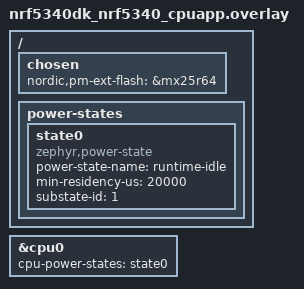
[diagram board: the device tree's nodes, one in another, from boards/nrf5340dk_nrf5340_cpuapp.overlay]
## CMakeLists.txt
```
# SPDX-License-Identifier: Apache-2.0

cmake_minimum_required(VERSION 3.20.0)
set(CMAKE_OBJCOPY arm-zephyr-eabi-objcopy)

set_property(GLOBAL 
    APPEND 
    PROPERTY extra_post_build_commands    
    COMMAND ${CMAKE_OBJCOPY} --output-target=binary --remove-section=_EXTFLASH_TEXT_SECTION_NAME --remove-section=_EXTFLASH_RODATA_SECTION_NAME --remove-section=.comment --remove-section=COMMON --remove-section=.eh_frame zephyr.elf zephyr.bin
    COMMAND ${CMAKE_OBJCOPY} --output-target=ihex --remove-section=_EXTFLASH_TEXT_SECTION_NAME --remove-section=_EXTFLASH_RODATA_SECTION_NAME --remove-section=.comment --remove-section=COMMON --remove-section=.eh_frame zephyr.elf zephyr.hex    
    COMMAND ${CMAKE_OBJCOPY} --output-target=binary --only-section=_EXTFLASH_TEXT_SECTION_NAME --only-section=_EXTFLASH_RODATA_SECTION_NAME zephyr.elf xip.bin
    COMMAND ${CMAKE_OBJCOPY} --output-target=ihex --only-section=_EXTFLASH_TEXT_SECTION_NAME --only-section=_EXTFLASH_RODATA_SECTION_NAME zephyr.elf xip.hex
    COMMAND python $ENV{ZEPHYR_BASE}/../bootloader/mcuboot/scripts/imgtool.py sign --key $ENV{ZEPHYR_BASE}/../bootloader/mcuboot/root-ec-p256.pem --header-size 0x200 --align 4 --version 0.0.0+0 --pad-header --slot-size 0x100000 xip.bin xip_signed.bin
    COMMAND ${CMAKE_OBJCOPY} --input-target=binary --output-target=ihex --change-address 0x10000000 --gap-fill=0xff xip_signed.bin xip_signed.hex
    COMMAND ${CMAKE_OBJCOPY} --input-target=binary --output-target=ihex --change-address 0x10230000 --gap-fill=0xff xip_signed.bin xip_moved_test_update.hex
    COMMAND echo "####### XIP hex generation #######"
)

SET(hci_rpmsg_b0n_OVERLAY_CONFIG "${CMAKE_CURRENT_SOURCE_DIR}/child_image/b0n.conf")

find_package(Zephyr REQUIRED HINTS $ENV{ZEPHYR_BASE})
project(xip_dma)

FILE(GLOB app_sources src/*.c)
target_sources(app PRIVATE ${app_sources})

# Run adc_thread from the external flash (XIP). No need to copy.
# zephyr_code_relocate(src/adc_thread.c EXTFLASH_TEXT NOCOPY)

# But still relocate (copy) the data to RAM
# zephyr_code_relocate(src/adc_thread.c RAM_DATA)

zephyr_code_relocate(FILES src/adc_thread.c LOCATION EXTFLASH_TEXT NOCOPY)
zephyr_code_relocate(FILES src/adc_thread.c LOCATION RAM_DATA)

zephyr_code_relocate(FILES src/const_var.c LOCATION EXTFLASH NOCOPY)
zephyr_code_relocate(FILES src/const_var.c LOCATION RAM_DATA)
```

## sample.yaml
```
sample:
  name: QSPI_XIP_DMA OTA
  description: This sample demonstrates how QSPI DMA coexists with QSPI XIP. In addition, it sets up the whole OTA framework.
tests:
  samples.bluetooth.peripheral_uart:
    build_only: true
    build_on_all: true
    platform_allow: nrf5340dk_nrf5340_cpuapp nrf7002dk_nrf5340_cpuapp
    tags: bluetooth ci_build
```

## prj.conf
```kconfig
CONFIG_STDOUT_CONSOLE=y
CONFIG_FLASH=y
CONFIG_SPI=y

CONFIG_ADC=y
CONFIG_ADC_NRFX_SAADC=y

CONFIG_ASSERT=y
CONFIG_LOG=y
CONFIG_LOG_BACKEND_RTT=y
CONFIG_USE_SEGGER_RTT=y
CONFIG_RTT_CONSOLE=y
CONFIG_LOG_PRINTK=y
CONFIG_LOG_BUFFER_SIZE=4096

CONFIG_CODE_DATA_RELOCATION=y
CONFIG_HAVE_CUSTOM_LINKER_SCRIPT=y
CONFIG_CUSTOM_LINKER_SCRIPT="linker_arm_nocopy.ld"
CONFIG_BUILD_NO_GAP_FILL=y
CONFIG_COVERAGE=n
CONFIG_XIP=y
CONFIG_NRFX_QSPI=y
CONFIG_NRF_ENABLE_CACHE=n

CONFIG_BOOTLOADER_MCUBOOT=y

# External flash configuration
CONFIG_NORDIC_QSPI_NOR=y
CONFIG_NORDIC_QSPI_NOR_FLASH_LAYOUT_PAGE_SIZE=4096
CONFIG_NORDIC_QSPI_NOR_STACK_WRITE_BUFFER_SIZE=16

# update application core and network core together in a zip file
CONFIG_MCUBOOT_IMAGE_VERSION="1.0.0+0"
CONFIG_UPDATEABLE_IMAGE_NUMBER=2
CONFIG_IMG_ERASE_PROGRESSIVELY=y
CONFIG_NRF53_UPGRADE_NETWORK_CORE=y

## thread monitor ##
CONFIG_THREAD_ANALYZER=y
CONFIG_THREAD_NAME=y
CONFIG_DEBUG_THREAD_INFO=y

CONFIG_BT=y
CONFIG_BT_PERIPHERAL=y
CONFIG_BT_DEVICE_NAME="XIP_DMA"
CONFIG_BT_DEVICE_APPEARANCE=833
CONFIG_BT_MAX_CONN=1
CONFIG_BT_MAX_PAIRED=1
CONFIG_BT_L2CAP_TX_MTU=498
CONFIG_BT_BUF_ACL_RX_SIZE=502
CONFIG_BT_BUF_ACL_TX_SIZE=502
# CONFIG_BT_CTLR_DATA_LENGTH_MAX=251
CONFIG_BT_NUS=y
CONFIG_DK_LIBRARY=y
CONFIG_SYSTEM_WORKQUEUE_STACK_SIZE=2048
CONFIG_MAIN_STACK_SIZE=2048
CONFIG_HEAP_MEM_POOL_SIZE=8192

CONFIG_FLASH=y
CONFIG_FLASH_PAGE_LAYOUT=y
CONFIG_FLASH_MAP=y
CONFIG_NVS=y
CONFIG_MPU_ALLOW_FLASH_WRITE=y
CONFIG_SETTINGS=y
CONFIG_STREAM_FLASH=y

CONFIG_PM_DEVICE=y
CONFIG_PM_DEVICE_RUNTIME=y
CONFIG_PM_DEVICE_RUNTIME_EXCLUSIVE=y
CONFIG_IDLE_STACK_SIZE=640
```

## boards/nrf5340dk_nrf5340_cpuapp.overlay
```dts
/*
 * Copyright (c) 2021 Nordic Semiconductor ASA
 *
 * SPDX-License-Identifier: LicenseRef-Nordic-5-Clause
 */

/ {
	chosen {
		nordic,pm-ext-flash = &mx25r64;
	};
	
	power-states {
		state0: state0 {
			compatible = "zephyr,power-state";
			power-state-name = "runtime-idle";
			min-residency-us = <20000>;			
			substate-id = <1>;
		};
	};	
};

&cpu0 {
	cpu-power-states = <&state0>;
};
```

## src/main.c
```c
/*
 * Copyright (c) 2016 Intel Corporation.
 *
 * SPDX-License-Identifier: Apache-2.0
 */

#include <zephyr/kernel.h>
#include <zephyr/drivers/flash.h>
#include <zephyr/storage/flash_map.h>
#include <zephyr/device.h>
#include <zephyr/devicetree.h>
#include <stdio.h>
#include <string.h>
#include <zephyr/bluetooth/bluetooth.h>
#include <zephyr/bluetooth/uuid.h>
#include <zephyr/bluetooth/gatt.h>
#include <zephyr/bluetooth/hci.h>
#include <bluetooth/services/nus.h>
#include <dk_buttons_and_leds.h>
#include <zephyr/logging/log.h>
#include <zephyr/logging/log_ctrl.h>
#include <zephyr/pm/device.h>
#include <zephyr/pm/device_runtime.h>
#include <nrfx.h>
#include <hal/nrf_power.h>
#include <zephyr/drivers/flash/nrf_qspi_nor.h>
#include <zephyr/pm/pm.h>
#include <hal/nrf_regulators.h>

LOG_MODULE_REGISTER(main);

#define DEVICE_NAME CONFIG_BT_DEVICE_NAME
#define DEVICE_NAME_LEN	(sizeof(DEVICE_NAME) - 1)

#define RUN_STATUS_LED DK_LED1
#define RUN_LED_BLINK_INTERVAL 1000

#define CON_STATUS_LED DK_LED2

static const struct bt_data ad[] = {
	BT_DATA_BYTES(BT_DATA_FLAGS, (BT_LE_AD_GENERAL | BT_LE_AD_NO_BREDR)),
	BT_DATA(BT_DATA_NAME_COMPLETE, DEVICE_NAME, DEVICE_NAME_LEN),
};
static struct bt_conn *current_conn;
static bool xip_enabled = true;
static bool xip_restore = false;

static void enable_xip(bool enable)
{
	const struct device *devQSPI;	
	// LOG_INF("=%d", enable);
	devQSPI = DEVICE_DT_GET(DT_INST(0, nordic_qspi_nor));
	nrf_qspi_nor_xip_enable(devQSPI, enable);
	xip_enabled = enable;
}
#if 1
/* Invoke Low Power/System Off specific Tasks */
void pm_state_set(enum pm_state state, uint8_t substate_id)
{
	ARG_UNUSED(substate_id);

	switch (state) {
	case PM_STATE_SOFT_OFF:
		nrf_regulators_system_off(NRF_REGULATORS);
		break;
	case PM_STATE_RUNTIME_IDLE:
		if (xip_enabled)
		{
			enable_xip(false);
			xip_restore = true;			
		}
		k_cpu_idle();			
		break;		
	default:
		printk("Unsupported power state %u\n\r", state);
		break;
	}
}

void restore_xip()
{
	if (xip_restore)
	{
		enable_xip(true);
		xip_restore = false;
		// LOG_INF("=%d", k_ticks_to_ms_floor32(ticks));
	}	
}
#endif

static void connected(struct bt_conn *conn, uint8_t err)
{
	char addr[BT_ADDR_LE_STR_LEN];

	if (err) {
		printk("Connection failed (err %u)", err);
		return;
	}

	bt_addr_le_to_str(bt_conn_get_dst(conn), addr, sizeof(addr));
	printk("Connected %s", (addr));

	current_conn = bt_conn_ref(conn);

	dk_set_led_on(CON_STATUS_LED);
}

static void disconnected(struct bt_conn *conn, uint8_t reason)
{
	char addr[BT_ADDR_LE_STR_LEN];

	bt_addr_le_to_str(bt_conn_get_dst(conn), addr, sizeof(addr));

	printk("Disconnected: %s (reason %u)", (addr), reason);

	if (current_conn) {
		bt_conn_unref(current_conn);
		current_conn = NULL;
		dk_set_led_off(CON_STATUS_LED);
	}
}

BT_CONN_CB_DEFINE(conn_callbacks) = {
	.connected    = connected,
	.disconnected = disconnected,
};

static void bt_receive_cb(struct bt_conn *conn, const uint8_t *const data,
			  uint16_t len)
{
	// int err;
	char addr[BT_ADDR_LE_STR_LEN] = {0};

	bt_addr_le_to_str(bt_conn_get_dst(conn), addr, ARRAY_SIZE(addr));

	printk("Received data from: %s", (addr));

}


static struct bt_nus_cb nus_cb = {
	.received = bt_receive_cb,
};

extern const k_tid_t adc_thread_id;
// #define SPI_FLASH_TEST_REGION_OFFSET 0x330000
#define SPI_FLASH_TEST_REGION_OFFSET 0
#define SPI_FLASH_SECTOR_SIZE        4096

void set_device_pm_state(void)
{	
	int err = 0;
	const struct device *devUart0;
	const struct device *devSPI4;

	devUart0 =  DEVICE_DT_GET(DT_NODELABEL(uart0));
	devSPI4 =	DEVICE_DT_GET(DT_NODELABEL(spi4));

	err = pm_device_runtime_enable(devUart0);

	//this is a workaround for SPI device since its driver doesn't support runtime PM
	err |= pm_device_action_run(devSPI4, PM_DEVICE_ACTION_SUSPEND);
	if (err) {
		printk("PM enable error (err: %d)", err);
	}	
}

// void button_changed(uint32_t button_state, uint32_t has_changed)
// {
// 	uint32_t buttons = button_state & has_changed;

// 	if (buttons & DK_BTN1_MSK) {
// 		printk("button1 isr");
// #ifdef CONFIG_PM_DEVICE		
// 		set_device_pm_state();
// #endif		
// 	}
// }

extern const uint32_t xip_const[4];
extern uint32_t get_xip_var(uint8_t i);

void main(void)
{
	const uint8_t expected[] = { 0x55, 0xaa, 0x66, 0x99 };
	const size_t len = sizeof(expected);
	uint8_t buf[sizeof(expected)];
	const struct device *flash_dev;
	const struct flash_area *fap;
	int rc, err;
	uint32_t loop = 0;
	uint32_t val;

	
	printk("\n\r### reset reason: 0x%08x  ####\r\n\n\r", NRF_RESET_S->RESETREAS);
	NRF_RESET_S->RESETREAS = 0xFFFFFFFF;

	set_device_pm_state();

	// err = dk_buttons_init(button_changed);
	// if (err) {
	// 	printk("Cannot init buttons (err: %d)", err);
	// }

	err = dk_leds_init();
	if (err) {
		printk("Cannot init LEDs (err: %d)", err);
	}

	err = bt_enable(NULL);
	if (err) {
		printk("bt enable error %d", err);
	}

	printk("Bluetooth initialized\r");

	err = bt_nus_init(&nus_cb);
	if (err) {
		printk("Failed to initialize UART service (err: %d)", err);
		return;
	}

	struct bt_le_adv_param adv_para;
	memset(&adv_para, 0, sizeof(struct bt_le_adv_param));
	adv_para.options = BT_LE_ADV_OPT_CONNECTABLE;
	adv_para.interval_min = BT_GAP_ADV_FAST_INT_MIN_2 * 3;
	adv_para.interval_max = BT_GAP_ADV_FAST_INT_MAX_2 * 2;

	err = bt_le_adv_start(&adv_para, ad, ARRAY_SIZE(ad), NULL,
			      0);

	if (err) {
		printk("Advertising failed to start (err %d)", err);
		return;
	}

	// flash_dev = DEVICE_DT_GET(DT_ALIAS(spi_flash0));
	rc = flash_area_open(PM_EXTERNAL_FLASH_ID, &fap);
	flash_dev = fap->fa_dev;

	if (!device_is_ready(flash_dev)) {
		printk("%s: device not ready.\n", flash_dev->name);
		return;
	}

	printk("\nXIP variable: %p\n", xip_const);
	val = xip_const[0] + 0x10;
	printk("XIP variable calculation result: %x\r\n", val);

	while (1)
	{
		printk("\n\r\n\r##### Loop: %d  start ######\n\r\n\r", ++loop);
		
		dk_set_led(RUN_STATUS_LED, loop%2);			
	
		k_thread_suspend(adc_thread_id);

		enable_xip(false);

		printk("\n#####Switched to QSPI DMA #####\n");
		printk("\nWatch the power consumption of QSPI DMA mode\n");
	
		k_sleep(K_SECONDS(10));		

		printk("\nTest 1: Flash erase\n");

		rc = flash_area_erase(fap, SPI_FLASH_TEST_REGION_OFFSET, SPI_FLASH_SECTOR_SIZE);
		if (rc != 0) {
			printk("Flash erase failed! %d\n", rc);
		} else {
			printk("Flash erase succeeded!\n");
		}

		printk("\nTest 2: Flash write\n");

		printk("Attempting to write %zu bytes\n", len);
		
		rc = flash_area_write(fap, SPI_FLASH_TEST_REGION_OFFSET, expected, len);
		if (rc != 0) {
			printk("Flash write failed! %d\n", rc);
			return;
		}

		memset(buf, 0, len);
		
		rc = flash_area_read(fap, SPI_FLASH_TEST_REGION_OFFSET, buf, len);
		if (rc != 0) {
			printk("Flash read failed! %d\n", rc);
			return;
		}

		if (memcmp(expected, buf, len) == 0) {
			printk("Data read matches data written. Good!!\n");
		} else {
			const uint8_t *wp = expected;
			const uint8_t *rp = buf;
			const uint8_t *rpe = rp + len;

			printk("Data read does not match data written!!\n");
			while (rp < rpe) {
				printk("%08x wrote %02x read %02x %s\n",
					(uint32_t)(SPI_FLASH_TEST_REGION_OFFSET + (rp - buf)),
					*wp, *rp, (*rp == *wp) ? "match" : "MISMATCH");
				++rp;
				++wp;
			}
		}

		enable_xip(true);
		k_thread_resume(adc_thread_id);
		printk("\n#####Switched to QSPI XIP #####\n");
		printk("\nWatch the power consumption of QSPI XIP mode\n");

		k_sleep(K_SECONDS(20));	

		printk("get xip var:0x%x\r\n", get_xip_var(loop));
		printk("XIP variable calculation result: %x\r\n", xip_const[1]+loop);
		
		printk("\n\r\n\r##### Loop: %d  end ######\n\r\n\r", loop);		

	}
}
```

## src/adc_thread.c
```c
/*
 * Copyright (c) 2020 Nordic Semiconductor ASA
 *
 * SPDX-License-Identifier: LicenseRef-BSD-5-Clause-Nordic
 */

#include <zephyr/kernel.h>
#include <zephyr/device.h>
#include <zephyr/devicetree.h>
#include <zephyr/drivers/gpio.h>
#include <zephyr/logging/log.h>
#include <zephyr/drivers/adc.h>
#include <hal/nrf_saadc.h>

LOG_MODULE_REGISTER(adc_thread, 3);

#define NUM_OF_CH 2
#define ADC_DEVICE_NAME		DT_NODE_FULL_NAME(DT_NODELABEL(adc))
#define ADC_RESOLUTION		12
#define ADC_OVERSAMPLING	4 /* 2^ADC_OVERSAMPLING samples are averaged */
#define ADC_MAX 		4096
#define BATTERY_MEAS_VOLTAGE_GAIN	6
#define ADC_GAIN		ADC_GAIN_1_6
#define ADC_REFERENCE		ADC_REF_INTERNAL
#define ADC_REF_INTERNAL_MV	600UL
#define ADC_ACQUISITION_TIME	ADC_ACQ_TIME(ADC_ACQ_TIME_MICROSECONDS, 10)
#define ADC_CHANNEL_ID		0
#define ADC_CHANNEL_INPUT	NRF_SAADC_INPUT_VDD
#define ADC_CHANNEL_ID2		1
#define ADC_CHANNEL_INPUT2	NRF_SAADC_INPUT_AIN1   //P0.05
#define ADC_SAMPLE_INTERVAL	20  //unit:s

#define BATTERY_VOLTAGE(sample) (sample * BATTERY_MEAS_VOLTAGE_GAIN	\
				 * ADC_REF_INTERNAL_MV / ADC_MAX)


static const struct device *adc_dev;
static int16_t adc_buffer[NUM_OF_CH];

static struct adc_sequence sequence = {
	.options	= NULL,
	.channels	= BIT(ADC_CHANNEL_ID),
	.buffer		= adc_buffer,
	.buffer_size	= sizeof(adc_buffer),
	.resolution	= ADC_RESOLUTION,
	.oversampling	= ADC_OVERSAMPLING,
	.calibrate	= false,
};
static struct adc_sequence sequence_calibrate = {
	.options	= NULL,
	.channels	= BIT(ADC_CHANNEL_ID),
	.buffer		= adc_buffer,
	.buffer_size	= sizeof(adc_buffer),
	.resolution	= ADC_RESOLUTION,
	.oversampling	= ADC_OVERSAMPLING,
	.calibrate	= true,
};

static bool calibrated;

void adc_sample_sync(void)
{
	int err;

	if (NUM_OF_CH == 2)
	{
		sequence.channels = BIT(ADC_CHANNEL_ID) | BIT(ADC_CHANNEL_ID2);
		sequence_calibrate.channels = BIT(ADC_CHANNEL_ID) | BIT(ADC_CHANNEL_ID2);
		sequence.oversampling  = NRF_SAADC_OVERSAMPLE_DISABLED;
		sequence_calibrate.oversampling  = NRF_SAADC_OVERSAMPLE_DISABLED;
	}
	if (likely(calibrated)) {		
		err = adc_read(adc_dev, &sequence);
	} else {
		err = adc_read(adc_dev, &sequence_calibrate);
		calibrated = true;
	}
	if (err) {
		LOG_WRN("ADC read err %d", err);
	} else {
		for (int i = 0; i < NUM_OF_CH; i++)
		{
			uint32_t voltage = BATTERY_VOLTAGE(adc_buffer[i]);
			LOG_INF("Voltage%d: %u mV / %d", i, voltage, adc_buffer[i]);
		}
	}			
}

int init_adc(void)
{
	int err;

	adc_dev = device_get_binding(ADC_DEVICE_NAME);
	if (!adc_dev) {
		LOG_ERR("Cannot get ADC device");
		return -ENXIO;
	}

	struct adc_channel_cfg channel_cfg = {
		.gain             = ADC_GAIN,
		.reference        = ADC_REFERENCE,
		.acquisition_time = ADC_ACQUISITION_TIME,
		.channel_id       = ADC_CHANNEL_ID,
		.differential	  = 0,
#if defined(CONFIG_ADC_CONFIGURABLE_INPUTS)
		.input_positive   = ADC_CHANNEL_INPUT,
#endif
	};
	err = adc_channel_setup(adc_dev, &channel_cfg);
	if (err) {
		LOG_ERR("Setting up the ADC channel%d failed", ADC_CHANNEL_ID);
		return err;
	}

	if (NUM_OF_CH == 2)
	{
		channel_cfg.channel_id = ADC_CHANNEL_ID2;
		channel_cfg.input_positive = ADC_CHANNEL_INPUT2;
		err = adc_channel_setup(adc_dev, &channel_cfg);
		if (err) {
			LOG_ERR("Setting up the ADC channel%d failed", ADC_CHANNEL_ID2);
			return err;
		}		
	}

	return 0;
}


void adc_thread(void)
{	
	
	LOG_INF("**ADC sampling example");
	init_adc();

	while (1) {                
        LOG_INF("ADC thread");
        adc_sample_sync();
        k_sleep(K_SECONDS(2)); 
	}
}

K_THREAD_DEFINE(adc_thread_id, 1024, adc_thread, NULL, NULL,
		NULL, 9, 0, 0);
```

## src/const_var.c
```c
/*
 * Copyright (c) 2020 Nordic Semiconductor ASA
 *
 * SPDX-License-Identifier: LicenseRef-BSD-5-Clause-Nordic
 */

#include <zephyr/kernel.h>
#include <zephyr/device.h>
#include <zephyr/devicetree.h>
#include <zephyr/drivers/gpio.h>
#include <zephyr/logging/log.h>
#include <zephyr/drivers/adc.h>
#include <hal/nrf_saadc.h>

LOG_MODULE_REGISTER(const_var, 3);


const uint32_t xip_const[4] = {0x11, 0x22, 0x33, 0x44};

uint32_t get_xip_var(uint8_t i)
{
    return xip_const[i%4];
}
```

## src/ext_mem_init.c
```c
/*
 * Copyright (c) 2022 Nordic Semiconductor ASA.
 *
 * SPDX-License-Identifier: Apache-2.0
 */

#include <errno.h>
#include <zephyr/init.h>
#include <zephyr/drivers/pinctrl.h>
#include <nrfx_qspi.h>
#include <hal/nrf_clock.h>
#include <zephyr/drivers/flash/nrf_qspi_nor.h>


int qspi_xip_init(const struct device *dev)
{
	ARG_UNUSED(dev);

	nrf_qspi_nor_xip_enable(DEVICE_DT_GET(DT_INST(0, nordic_qspi_nor)), false);

	nrf_qspi_nor_xip_enable(DEVICE_DT_GET(DT_INST(0, nordic_qspi_nor)), true);

    printk("in QSPI XIP mode\r\n");
	return 0;
}

SYS_INIT(qspi_xip_init, POST_KERNEL, CONFIG_APPLICATION_INIT_PRIORITY);
```
